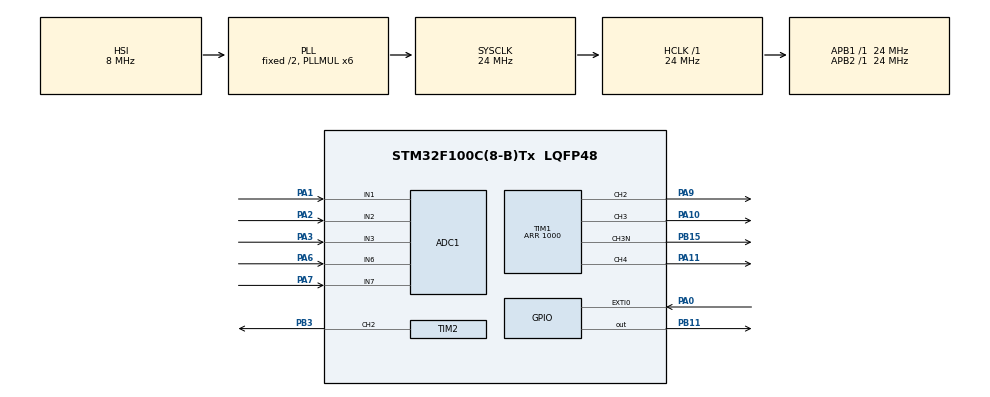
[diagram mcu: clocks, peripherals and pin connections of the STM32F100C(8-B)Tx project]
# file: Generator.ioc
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Mcu.Family=STM32F1
SH.S_TIM1_CH4.0=TIM1_CH4,PWM Generation4 CH4
SH.ADCx_IN2.0=ADC1_IN2,IN2
ADC1.SamplingTime-6\#ChannelRegularConversion=ADC_SAMPLETIME_1CYCLE_5
PB11.GPIO_PuPd=GPIO_NOPULL
TIM2.Channel-PWM\ Generation2\ CH2=TIM_CHANNEL_2
PB11.Signal=GPIO_Output
PB15.Signal=TIM1_CH3N
ADC1.Channel-8\#ChannelRegularConversion=ADC_CHANNEL_3
RCC.SYSCLKSource=RCC_SYSCLKSOURCE_PLLCLK
ProjectManager.StackSize=0x400
PB11.GPIO_Speed=GPIO_SPEED_FREQ_HIGH
VP_TIM2_VS_ClockSourceITR.Mode=TriggerSource_ITR0
TIM1.Channel-PWM\ Generation4\ CH4=TIM_CHANNEL_4
RCC.HCLKFreq_Value=24000000
SH.ADCx_IN3.0=ADC1_IN3,IN3
RCC.APB2TimFreq_Value=24000000
Dma.ADC1.0.Direction=DMA_PERIPH_TO_MEMORY
PA10.GPIO_ModeDefaultPP=GPIO_MODE_AF_PP
Dma.ADC1.0.MemDataAlignment=DMA_MDATAALIGN_HALFWORD
RCC.AHBFreq_Value=24000000
RCC.PLLMUL=RCC_PLL_MUL6
ADC1.Channel-6\#ChannelRegularConversion=ADC_CHANNEL_1
NVIC.TIM1_TRG_COM_TIM17_IRQn=true\:5\:0\:false\:false\:true\:true\:true\:true
PA14.Mode=Serial_Wire
Dma.ADC1.0.PeriphInc=DMA_PINC_DISABLE
TIM1.DeadTime=5
NVIC.TIM2_IRQn=true\:5\:0\:false\:false\:true\:true\:true\:true
VP_FREERTOS_VS_CMSIS_V1.Mode=CMSIS_V1
VP_TIM1_VS_ClockSourceINT.Mode=Internal
Mcu.Package=LQFP48
PA6.Signal=ADCx_IN6
NVIC.TimeBase=TIM7_IRQn
NVIC.TimeBaseIP=TIM7
PA10.Signal=S_TIM1_CH3
TIM2.Pulse-PWM\ Generation2\ CH2=1
TIM2.TIM_MasterOutputTrigger=TIM_TRGO_RESET
SH.ADCx_IN1.0=ADC1_IN1,IN1
RCC.APB1TimFreq_Value=24000000
TIM1.Period=1000
Dma.Request0=ADC1
ADC1.Rank-6\#ChannelRegularConversion=1
ADC1.SamplingTime-8\#ChannelRegularConversion=ADC_SAMPLETIME_1CYCLE_5
NVIC.TIM7_IRQn=true\:0\:0\:false\:false\:true\:false\:false\:true
PA3.Signal=ADCx_IN3
ADC1.Channel-10\#ChannelRegularConversion=ADC_CHANNEL_7
TIM1.OCPolarity_3=TIM_OCPOLARITY_LOW
Dma.ADC1.0.Instance=DMA1_Channel1
TIM1.OCPolarity_2=TIM_OCPOLARITY_LOW
FREERTOS.Tasks01=defaultTask,0,128,StartDefaultTask,Default,NULL,Dynamic,NULL,NULL;userDisplay,-3,128,userDisplayTask,Default,NULL,Dynamic,NULL,NULL
TIM1.OCPolarity_4=TIM_OCPOLARITY_HIGH
ADC1.Rank-10\#ChannelRegularConversion=5
SH.ADCx_IN6.0=ADC1_IN6,IN6
ADC1.Rank-8\#ChannelRegularConversion=3
VP_SYS_VS_tim7.Mode=TIM7
PA0-WKUP.Signal=GPXTI0
ADC1.Channel-7\#ChannelRegularConversion=ADC_CHANNEL_2
PA13.Signal=SYS_JTMS-SWDIO
TIM1.AutoReloadPreload=TIM_AUTORELOAD_PRELOAD_ENABLE
SH.S_TIM2_CH2.0=TIM2_CH2,PWM Generation2 CH2
Dma.ADC1.0.PeriphDataAlignment=DMA_PDATAALIGN_HALFWORD
ProjectManager.TargetToolchain=SW4STM32
Dma.ADC1.0.Mode=DMA_CIRCULAR
SH.ADCx_IN7.0=ADC1_IN7,IN7
VP_TIM2_VS_ControllerModeClock.Mode=Clock Mode
Dma.ADC1.0.Priority=DMA_PRIORITY_LOW
PA9.Signal=S_TIM1_CH2
TIM1.Channel-PWM\ Generation2\ CH2=TIM_CHANNEL_2
TIM1.Channel-PWM\ Generation3\ CH3\ CH3N=TIM_CHANNEL_3
PA11.GPIO_ModeDefaultPP=GPIO_MODE_AF_OD
PB11.GPIO_ModeDefaultOutputPP=GPIO_MODE_OUTPUT_OD
PA1.Signal=ADCx_IN1
board=custom
PB15.Mode=PWM Generation3 CH3 CH3N
TIM1.TIM_MasterOutputTrigger=TIM_TRGO_UPDATE
RCC.APB2Freq_Value=24000000
TIM1.OCNPolarity_3=TIM_OCNPOLARITY_LOW
SH.S_TIM1_CH2.0=TIM1_CH2,PWM Generation2 CH2
ADC1.SamplingTime-10\#ChannelRegularConversion=ADC_SAMPLETIME_1CYCLE_5
TIM2.Period=50
ADC1.Rank-9\#ChannelRegularConversion=4
ADC1.NbrOfConversion=5
PA13.Mode=Serial_Wire
Mcu.Name=STM32F100C(8-B)Tx
PA2.Signal=ADCx_IN2
ADC1.Channel-9\#ChannelRegularConversion=ADC_CHANNEL_6
NVIC.TIM1_CC_IRQn=true\:5\:0\:false\:false\:true\:true\:true\:true
PB3.Signal=S_TIM2_CH2
NVIC.EXTI0_IRQn=true\:5\:0\:false\:false\:true\:true\:true\:true
RCC.SYSCLKFreq_VALUE=24000000
ADC1.master=1
PA11.Signal=S_TIM1_CH4
Dma.ADC1.0.MemInc=DMA_MINC_ENABLE
PA14.Signal=SYS_JTCK-SWCLK
ProjectManager.HeapSize=0x200
SH.S_TIM1_CH3.0=TIM1_CH3,PWM Generation3 CH3 CH3N
ADC1.Rank-7\#ChannelRegularConversion=2
NVIC.TIM1_UP_TIM16_IRQn=true\:5\:0\:false\:false\:true\:true\:true\:true
NVIC.PriorityGroup=NVIC_PRIORITYGROUP_4
ADC1.NbrOfConversionFlag=1
TIM2.TIM_MasterSlaveMode=TIM_MASTERSLAVEMODE_DISABLE
TIM2.AutoReloadPreload=TIM_AUTORELOAD_PRELOAD_ENABLE
PA0-WKUP.GPIO_PuPd=GPIO_PULLDOWN
ADC1.SamplingTime-9\#ChannelRegularConversion=ADC_SAMPLETIME_1CYCLE_5
ADC1.SamplingTime-7\#ChannelRegularConversion=ADC_SAMPLETIME_1CYCLE_5
NVIC.DMA1_Channel1_IRQn=true\:5\:0\:false\:false\:true\:true\:false\:true
RCC.APB1Freq_Value=24000000
TIM1.TIM_MasterSlaveMode=TIM_MASTERSLAVEMODE_ENABLE
PA7.Signal=ADCx_IN7

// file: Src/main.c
/* USER CODE BEGIN Header */
/**
  ******************************************************************************
  * @file           : main.c
  * @brief          : Main program body
  ******************************************************************************
  * @attention
  *
  * <h2><center>&copy; Copyright (c) 2021 STMicroelectronics.
  * All rights reserved.</center></h2>
  *
  * This software component is licensed by ST under Ultimate Liberty license
  * SLA0044, the "License"; You may not use this file except in compliance with
  * the License. You may obtain a copy of the License at:
  *                             www.st.com/SLA0044
  *
  ******************************************************************************
  */
/* USER CODE END Header */
#include "main.h"
#include "cmsis_os.h"

ADC_HandleTypeDef hadc1;
DMA_HandleTypeDef hdma_adc1;

TIM_HandleTypeDef htim1;
TIM_HandleTypeDef htim2;

osThreadId defaultTaskHandle;
osThreadId userDisplayHandle;

void SystemClock_Config(void);
static void MX_GPIO_Init(void);
static void MX_DMA_Init(void);
static void MX_TIM1_Init(void);
static void MX_ADC1_Init(void);
static void MX_TIM2_Init(void);
void StartDefaultTask(void const * argument);
void userDisplayTask(void const * argument);

int main(void)
{

  /* MCU Configuration--------------------------------------------------------*/

  /* Reset of all peripherals, Initializes the Flash interface and the Systick. */
  HAL_Init();

  /* Configure the system clock */
  SystemClock_Config();

  /* Initialize all configured peripherals */
  MX_GPIO_Init();
  MX_DMA_Init();
  MX_TIM1_Init();
  MX_ADC1_Init();
  MX_TIM2_Init();
  /* USER CODE BEGIN 2 */
  kernel_init(&htim1, &htim2, &hadc1, &hdma_adc1);
  /* USER CODE END 2 */

  /* Create the thread(s) */
  /* definition and creation of defaultTask */
  osThreadDef(defaultTask, StartDefaultTask, osPriorityNormal, 0, 128);
  defaultTaskHandle = osThreadCreate(osThread(defaultTask), NULL);

  /* definition and creation of userDisplay */
  osThreadDef(userDisplay, userDisplayTask, osPriorityIdle, 0, 128);
  userDisplayHandle = osThreadCreate(osThread(userDisplay), NULL);

  /* Start scheduler */
  osKernelStart();

  /* We should never get here as control is now taken by the scheduler */
  /* Infinite loop */
  while (1)
  {

  }
}

void SystemClock_Config(void)
{
  RCC_OscInitTypeDef RCC_OscInitStruct = {0};
  RCC_ClkInitTypeDef RCC_ClkInitStruct = {0};
  RCC_PeriphCLKInitTypeDef PeriphClkInit = {0};

  /** Initializes the RCC Oscillators according to the specified parameters
  * in the RCC_OscInitTypeDef structure.
  */
  RCC_OscInitStruct.OscillatorType = RCC_OSCILLATORTYPE_HSI;
  RCC_OscInitStruct.HSIState = RCC_HSI_ON;
  RCC_OscInitStruct.HSICalibrationValue = RCC_HSICALIBRATION_DEFAULT;
  RCC_OscInitStruct.PLL.PLLState = RCC_PLL_ON;
  RCC_OscInitStruct.PLL.PLLSource = RCC_PLLSOURCE_HSI_DIV2;
  RCC_OscInitStruct.PLL.PLLMUL = RCC_PLL_MUL6;
  if (HAL_RCC_OscConfig(&RCC_OscInitStruct) != HAL_OK)
  {
    Error_Handler();
  }
  /** Initializes the CPU, AHB and APB buses clocks
  */
  RCC_ClkInitStruct.ClockType = RCC_CLOCKTYPE_HCLK|RCC_CLOCKTYPE_SYSCLK
                              |RCC_CLOCKTYPE_PCLK1|RCC_CLOCKTYPE_PCLK2;
  RCC_ClkInitStruct.SYSCLKSource = RCC_SYSCLKSOURCE_PLLCLK;
  RCC_ClkInitStruct.AHBCLKDivider = RCC_SYSCLK_DIV1;
  RCC_ClkInitStruct.APB1CLKDivider = RCC_HCLK_DIV1;
  RCC_ClkInitStruct.APB2CLKDivider = RCC_HCLK_DIV1;

  if (HAL_RCC_ClockConfig(&RCC_ClkInitStruct, FLASH_LATENCY_0) != HAL_OK)
  {
    Error_Handler();
  }
  PeriphClkInit.PeriphClockSelection = RCC_PERIPHCLK_ADC;
  PeriphClkInit.AdcClockSelection = RCC_ADCPCLK2_DIV2;
  if (HAL_RCCEx_PeriphCLKConfig(&PeriphClkInit) != HAL_OK)
  {
    Error_Handler();
  }
}

static void MX_ADC1_Init(void)
{

  ADC_ChannelConfTypeDef sConfig = {0};

  /** Common config
  */
  hadc1.Instance = ADC1;
  hadc1.Init.ScanConvMode = ADC_SCAN_ENABLE;
  hadc1.Init.ContinuousConvMode = DISABLE;
  hadc1.Init.DiscontinuousConvMode = DISABLE;
  hadc1.Init.ExternalTrigConv = ADC_SOFTWARE_START;
  hadc1.Init.DataAlign = ADC_DATAALIGN_RIGHT;
  hadc1.Init.NbrOfConversion = 5;
  if (HAL_ADC_Init(&hadc1) != HAL_OK)
  {
    Error_Handler();
  }
  /** Configure Regular Channel
  */
  sConfig.Channel = ADC_CHANNEL_1;
  sConfig.Rank = ADC_REGULAR_RANK_1;
  sConfig.SamplingTime = ADC_SAMPLETIME_1CYCLE_5;
  if (HAL_ADC_ConfigChannel(&hadc1, &sConfig) != HAL_OK)
  {
    Error_Handler();
  }
  /** Configure Regular Channel
  */
  sConfig.Channel = ADC_CHANNEL_2;
  sConfig.Rank = ADC_REGULAR_RANK_2;
  if (HAL_ADC_ConfigChannel(&hadc1, &sConfig) != HAL_OK)
  {
    Error_Handler();
  }
  /** Configure Regular Channel
  */
  sConfig.Channel = ADC_CHANNEL_3;
  sConfig.Rank = ADC_REGULAR_RANK_3;
  if (HAL_ADC_ConfigChannel(&hadc1, &sConfig) != HAL_OK)
  {
    Error_Handler();
  }
  /** Configure Regular Channel
  */
  sConfig.Channel = ADC_CHANNEL_6;
  sConfig.Rank = ADC_REGULAR_RANK_4;
  if (HAL_ADC_ConfigChannel(&hadc1, &sConfig) != HAL_OK)
  {
    Error_Handler();
  }
  /** Configure Regular Channel
  */
  sConfig.Channel = ADC_CHANNEL_7;
  sConfig.Rank = ADC_REGULAR_RANK_5;
  if (HAL_ADC_ConfigChannel(&hadc1, &sConfig) != HAL_OK)
  {
    Error_Handler();
  }

}

static void MX_TIM1_Init(void)
{

  TIM_ClockConfigTypeDef sClockSourceConfig = {0};
  TIM_MasterConfigTypeDef sMasterConfig = {0};
  TIM_OC_InitTypeDef sConfigOC = {0};
  TIM_BreakDeadTimeConfigTypeDef sBreakDeadTimeConfig = {0};

  htim1.Instance = TIM1;
  htim1.Init.Prescaler = 0;
  htim1.Init.CounterMode = TIM_COUNTERMODE_UP;
  htim1.Init.Period = 1000;
  htim1.Init.ClockDivision = TIM_CLOCKDIVISION_DIV1;
  htim1.Init.RepetitionCounter = 0;
  htim1.Init.AutoReloadPreload = TIM_AUTORELOAD_PRELOAD_ENABLE;
  if (HAL_TIM_Base_Init(&htim1) != HAL_OK)
  {
    Error_Handler();
  }
  sClockSourceConfig.ClockSource = TIM_CLOCKSOURCE_INTERNAL;
  if (HAL_TIM_ConfigClockSource(&htim1, &sClockSourceConfig) != HAL_OK)
  {
    Error_Handler();
  }
  if (HAL_TIM_PWM_Init(&htim1) != HAL_OK)
  {
    Error_Handler();
  }
  sMasterConfig.MasterOutputTrigger = TIM_TRGO_UPDATE;
  sMasterConfig.MasterSlaveMode = TIM_MASTERSLAVEMODE_ENABLE;
  if (HAL_TIMEx_MasterConfigSynchronization(&htim1, &sMasterConfig) != HAL_OK)
  {
    Error_Handler();
  }
  sConfigOC.OCMode = TIM_OCMODE_PWM1;
  sConfigOC.Pulse = 0;
  sConfigOC.OCPolarity = TIM_OCPOLARITY_LOW;
  sConfigOC.OCNPolarity = TIM_OCNPOLARITY_HIGH;
  sConfigOC.OCFastMode = TIM_OCFAST_DISABLE;
  sConfigOC.OCIdleState = TIM_OCIDLESTATE_RESET;
  sConfigOC.OCNIdleState = TIM_OCNIDLESTATE_RESET;
  if (HAL_TIM_PWM_ConfigChannel(&htim1, &sConfigOC, TIM_CHANNEL_2) != HAL_OK)
  {
    Error_Handler();
  }
  sConfigOC.OCNPolarity = TIM_OCNPOLARITY_LOW;
  if (HAL_TIM_PWM_ConfigChannel(&htim1, &sConfigOC, TIM_CHANNEL_3) != HAL_OK)
  {
    Error_Handler();
  }
  sConfigOC.OCPolarity = TIM_OCPOLARITY_HIGH;
  if (HAL_TIM_PWM_ConfigChannel(&htim1, &sConfigOC, TIM_CHANNEL_4) != HAL_OK)
  {
    Error_Handler();
  }
  sBreakDeadTimeConfig.OffStateRunMode = TIM_OSSR_DISABLE;
  sBreakDeadTimeConfig.OffStateIDLEMode = TIM_OSSI_DISABLE;
  sBreakDeadTimeConfig.LockLevel = TIM_LOCKLEVEL_OFF;
  sBreakDeadTimeConfig.DeadTime = 5;
  sBreakDeadTimeConfig.BreakState = TIM_BREAK_DISABLE;
  sBreakDeadTimeConfig.BreakPolarity = TIM_BREAKPOLARITY_HIGH;
  sBreakDeadTimeConfig.AutomaticOutput = TIM_AUTOMATICOUTPUT_DISABLE;
  if (HAL_TIMEx_ConfigBreakDeadTime(&htim1, &sBreakDeadTimeConfig) != HAL_OK)
  {
    Error_Handler();
  }
  HAL_TIM_MspPostInit(&htim1);

}

static void MX_TIM2_Init(void)
{

  TIM_SlaveConfigTypeDef sSlaveConfig = {0};
  TIM_MasterConfigTypeDef sMasterConfig = {0};
  TIM_OC_InitTypeDef sConfigOC = {0};

  htim2.Instance = TIM2;
  htim2.Init.Prescaler = 0;
  htim2.Init.CounterMode = TIM_COUNTERMODE_UP;
  htim2.Init.Period = 50;
  htim2.Init.ClockDivision = TIM_CLOCKDIVISION_DIV1;
  htim2.Init.AutoReloadPreload = TIM_AUTORELOAD_PRELOAD_ENABLE;
  if (HAL_TIM_Base_Init(&htim2) != HAL_OK)
  {
    Error_Handler();
  }
  if (HAL_TIM_PWM_Init(&htim2) != HAL_OK)
  {
    Error_Handler();
  }
  sSlaveConfig.SlaveMode = TIM_SLAVEMODE_EXTERNAL1;
  sSlaveConfig.InputTrigger = TIM_TS_ITR0;
  if (HAL_TIM_SlaveConfigSynchro(&htim2, &sSlaveConfig) != HAL_OK)
  {
    Error_Handler();
  }
  sMasterConfig.MasterOutputTrigger = TIM_TRGO_RESET;
  sMasterConfig.MasterSlaveMode = TIM_MASTERSLAVEMODE_DISABLE;
  if (HAL_TIMEx_MasterConfigSynchronization(&htim2, &sMasterConfig) != HAL_OK)
  {
    Error_Handler();
  }
  sConfigOC.OCMode = TIM_OCMODE_PWM1;
  sConfigOC.Pulse = 1;
  sConfigOC.OCPolarity = TIM_OCPOLARITY_HIGH;
  sConfigOC.OCFastMode = TIM_OCFAST_DISABLE;
  if (HAL_TIM_PWM_ConfigChannel(&htim2, &sConfigOC, TIM_CHANNEL_2) != HAL_OK)
  {
    Error_Handler();
  }
  HAL_TIM_MspPostInit(&htim2);

}

static void MX_DMA_Init(void)
{

  /* DMA controller clock enable */
  __HAL_RCC_DMA1_CLK_ENABLE();

  /* DMA interrupt init */
  /* DMA1_Channel1_IRQn interrupt configuration */
  HAL_NVIC_SetPriority(DMA1_Channel1_IRQn, 5, 0);
  HAL_NVIC_EnableIRQ(DMA1_Channel1_IRQn);

}

static void MX_GPIO_Init(void)
{
  GPIO_InitTypeDef GPIO_InitStruct = {0};

  /* GPIO Ports Clock Enable */
  __HAL_RCC_GPIOA_CLK_ENABLE();
  __HAL_RCC_GPIOB_CLK_ENABLE();

  /*Configure GPIO pin Output Level */
  HAL_GPIO_WritePin(GPIOB, GPIO_PIN_11, GPIO_PIN_RESET);

  /*Configure GPIO pin : PA0 */
  GPIO_InitStruct.Pin = GPIO_PIN_0;
  GPIO_InitStruct.Mode = GPIO_MODE_IT_RISING;
  GPIO_InitStruct.Pull = GPIO_PULLDOWN;
  HAL_GPIO_Init(GPIOA, &GPIO_InitStruct);

  /*Configure GPIO pin : PB11 */
  GPIO_InitStruct.Pin = GPIO_PIN_11;
  GPIO_InitStruct.Mode = GPIO_MODE_OUTPUT_OD;
  GPIO_InitStruct.Pull = GPIO_NOPULL;
  GPIO_InitStruct.Speed = GPIO_SPEED_FREQ_HIGH;
  HAL_GPIO_Init(GPIOB, &GPIO_InitStruct);

  /* EXTI interrupt init*/
  HAL_NVIC_SetPriority(EXTI0_IRQn, 5, 0);
  HAL_NVIC_EnableIRQ(EXTI0_IRQn);

}

void StartDefaultTask(void const * argument)
{
  /* USER CODE BEGIN 5 */
  kernel_mainLoop();
  /* USER CODE END 5 */
}

void userDisplayTask(void const * argument)
{
  for(;;)
  {
    osDelay(1);
  }
}

 /**
  * @brief  Period elapsed callback in non blocking mode
  * @note   This function is called  when TIM7 interrupt took place, inside
  * HAL_TIM_IRQHandler(). It makes a direct call to HAL_IncTick() to increment
  * a global variable "uwTick" used as application time base.
  * @param  htim : TIM handle
  * @retval None
  */
void HAL_TIM_PeriodElapsedCallback(TIM_HandleTypeDef *htim)
{
  if (htim->Instance == TIM7) {
    HAL_IncTick();
  }
  /* USER CODE BEGIN Callback 1 */
  if (htim->Instance == TIM1)
  {
	  TIM1_PeriodElapsedCallback();
  }
  /* USER CODE END Callback 1 */
}

void Error_Handler(void)
{
  __disable_irq();
  while (1)
  {
  }
}

/************************ (C) COPYRIGHT STMicroelectronics *****END OF FILE****/
